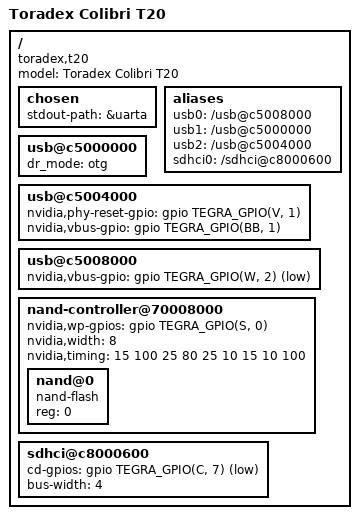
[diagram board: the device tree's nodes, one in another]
/dts-v1/;

#include "tegra20.dtsi"

/ {
	model = "Toradex Colibri T20";
	compatible = "toradex,t20", "nvidia,tegra20";

	chosen {
		stdout-path = &uarta;
	};

	aliases {
		usb0 = "/usb@c5008000";
		usb1 = "/usb@c5000000";
		usb2 = "/usb@c5004000";
		sdhci0 = "/sdhci@c8000600";
	};

	usb@c5000000 {
		dr_mode = "otg";
	};

	usb@c5004000 {
		nvidia,phy-reset-gpio = <&gpio TEGRA_GPIO(V, 1) GPIO_ACTIVE_HIGH>;
		nvidia,vbus-gpio = <&gpio TEGRA_GPIO(BB, 1) GPIO_ACTIVE_HIGH>;
	};

	usb@c5008000 {
		nvidia,vbus-gpio = <&gpio TEGRA_GPIO(W, 2) GPIO_ACTIVE_LOW>;
	};

	nand-controller@70008000 {
		nvidia,wp-gpios = <&gpio TEGRA_GPIO(S, 0) GPIO_ACTIVE_HIGH>;
		nvidia,width = <8>;
		nvidia,timing = <15 100 25 80 25 10 15 10 100>;

		nand@0 {
			reg = <0>;
			compatible = "nand-flash";
		};
	};

	sdhci@c8000600 {
		status = "okay";
		cd-gpios = <&gpio TEGRA_GPIO(C, 7) GPIO_ACTIVE_LOW>;
		bus-width = <4>;
	};
};
